# STM32L162ZDT6 register map
File version: 1.0
Registers are 32-bit, access not given, reset 0x0 unless marked. A register's access mark holds for its fields unless they carry their own. Offsets are from the block's base; [hi:lo] are bit positions; {n}, {i} and the like mark numbered series; 'fields as' and 'values as' point back to an identical list.

## GPIOA
Base 0x40020000
Same registers: GPIOB 0x40020400, GPIOC 0x40020800, GPIOD 0x40020C00, GPIOE 0x40021000, GPIOH 0x40021400, GPIOF 0x40021800, GPIOG 0x40021C00
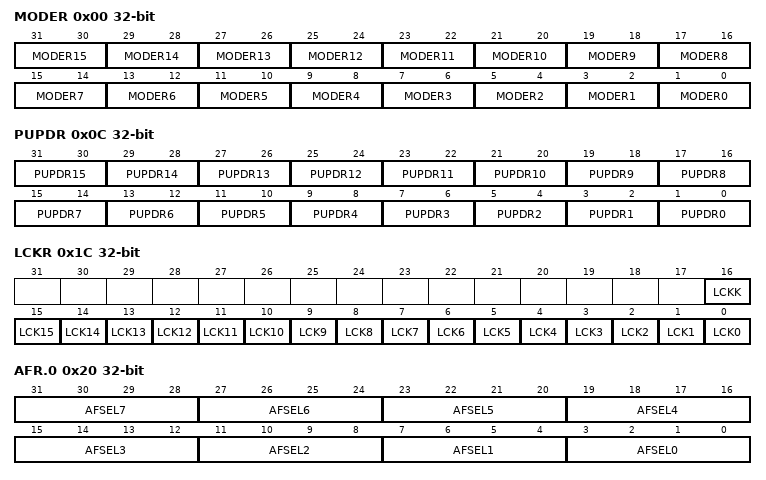
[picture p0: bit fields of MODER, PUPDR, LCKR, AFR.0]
0x00 MODER
  [2n+1:2n] MODER{n} (n=0..15)
0x04 OTYPER
0x08 OSPEEDR
0x0C PUPDR
  [2n+1:2n] PUPDR{n} (n=0..15)
0x10 IDR
0x14 ODR
0x18 BSRR
0x1C LCKR
  [16] LCKK, [n] LCK{n} (n=0..15)
0x20 AFR.0
  [4n+3:4n] AFSEL{n} (n=0..7)
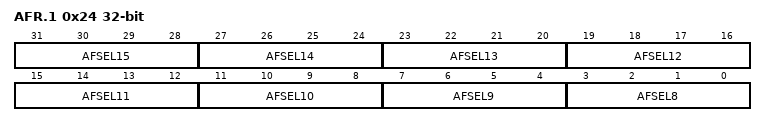
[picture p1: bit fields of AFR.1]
0x24 AFR.1
  [4n-29:4n-32] AFSEL{n} (n=8..15)
0x28 BRR

## CRC
Base 0x40023000
0x00 DR
0x04 IDR 8-bit
0x08 CR
  [0] RESET

## RCC
Base 0x40023800
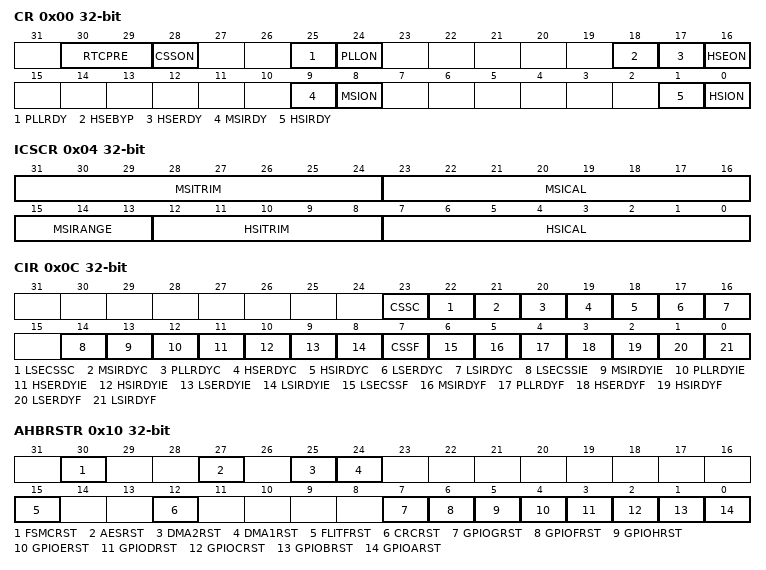
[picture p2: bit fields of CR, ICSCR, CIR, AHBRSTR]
0x00 CR
  [30:29] RTCPRE, [28] CSSON, [25] PLLRDY, [24] PLLON, [18] HSEBYP, [17] HSERDY, [16] HSEON, [9] MSIRDY, [8] MSION, [1] HSIRDY, [0] HSION
0x04 ICSCR
  [31:24] MSITRIM, [23:16] MSICAL, [15:13] MSIRANGE, [12:8] HSITRIM, [7:0] HSICAL
0x08 CFGR
  [30:28] MCOPRE, [26] MCOSEL_HSE, [26:25] MCOSEL_LSI, [24] MCOSEL_SYSCLK, [23] PLLDIV3, [23:22] PLLDIV4, [21:18] PLLMUL, [16] PLLSRC, [13:11] PPRE2, [10:8] PPRE1, [7:4] HPRE, [3:2] SWS, [1:0] SW
0x0C CIR
  [23] CSSC, [22] LSECSSC, [21] MSIRDYC, [20] PLLRDYC, [19] HSERDYC, [18] HSIRDYC, [17] LSERDYC, [16] LSIRDYC, [14] LSECSSIE, [13] MSIRDYIE, [12] PLLRDYIE, [11] HSERDYIE, [10] HSIRDYIE, [9] LSERDYIE, [8] LSIRDYIE, [7] CSSF, [6] LSECSSF, [5] MSIRDYF, [4] PLLRDYF, [3] HSERDYF, [2] HSIRDYF, [1] LSERDYF, [0] LSIRDYF
0x10 AHBRSTR
  [30] FSMCRST, [27] AESRST, [25] DMA2RST, [24] DMA1RST, [15] FLITFRST, [12] CRCRST, [7] GPIOGRST, [6] GPIOFRST, [5] GPIOHRST, [4] GPIOERST, [3] GPIODRST, [2] GPIOCRST, [1] GPIOBRST, [0] GPIOARST
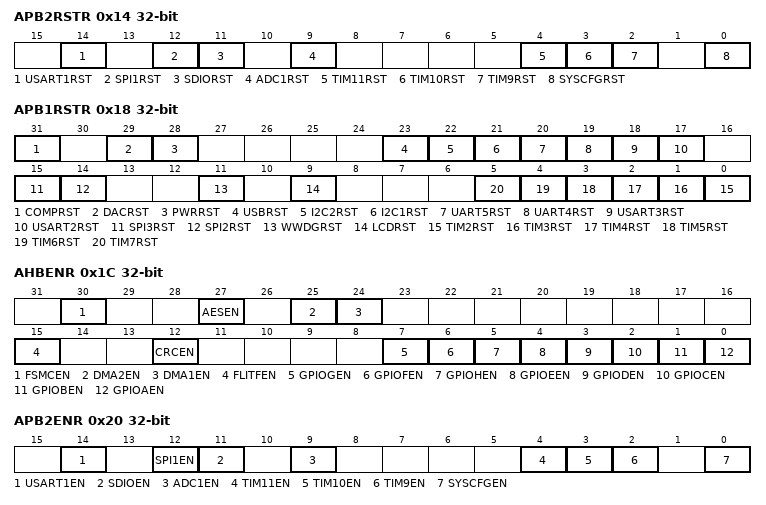
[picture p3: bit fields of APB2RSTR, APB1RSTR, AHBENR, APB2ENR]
0x14 APB2RSTR
  [14] USART1RST, [12] SPI1RST, [11] SDIORST, [9] ADC1RST, [4] TIM11RST, [3] TIM10RST, [2] TIM9RST, [0] SYSCFGRST
0x18 APB1RSTR
  [31] COMPRST, [29] DACRST, [28] PWRRST, [23] USBRST, [22] I2C2RST, [21] I2C1RST, [20] UART5RST, [19] UART4RST, [18] USART3RST, [17] USART2RST, [15] SPI3RST, [14] SPI2RST, [11] WWDGRST, [9] LCDRST, [n-2] TIM{n}RST (n=2..7)
0x1C AHBENR
  [30] FSMCEN, [27] AESEN, [25] DMA2EN, [24] DMA1EN, [15] FLITFEN, [12] CRCEN, [7] GPIOGEN, [6] GPIOFEN, [5] GPIOHEN, [4] GPIOEEN, [3] GPIODEN, [2] GPIOCEN, [1] GPIOBEN, [0] GPIOAEN
0x20 APB2ENR
  [14] USART1EN, [12] SPI1EN, [11] SDIOEN, [9] ADC1EN, [4] TIM11EN, [3] TIM10EN, [2] TIM9EN, [0] SYSCFGEN
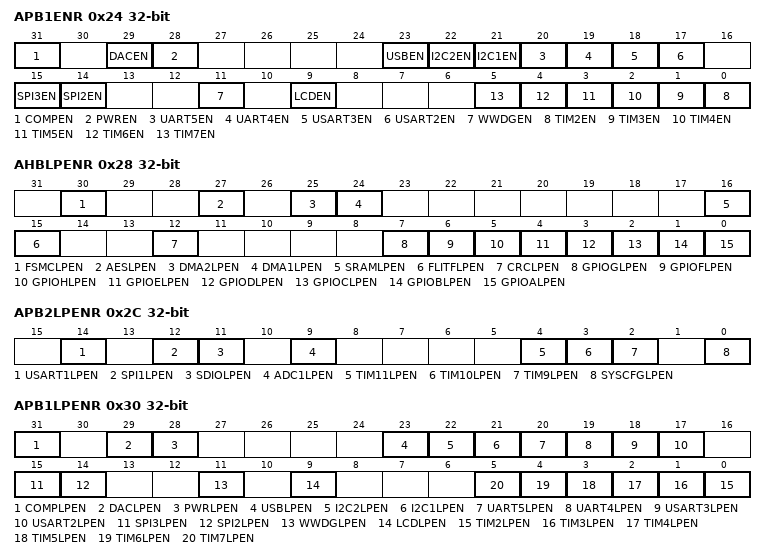
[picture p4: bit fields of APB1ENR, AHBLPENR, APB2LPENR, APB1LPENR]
0x24 APB1ENR
  [31] COMPEN, [29] DACEN, [28] PWREN, [23] USBEN, [22] I2C2EN, [21] I2C1EN, [20] UART5EN, [19] UART4EN, [18] USART3EN, [17] USART2EN, [15] SPI3EN, [14] SPI2EN, [11] WWDGEN, [9] LCDEN, [n-2] TIM{n}EN (n=2..7)
0x28 AHBLPENR
  [30] FSMCLPEN, [27] AESLPEN, [25] DMA2LPEN, [24] DMA1LPEN, [16] SRAMLPEN, [15] FLITFLPEN, [12] CRCLPEN, [7] GPIOGLPEN, [6] GPIOFLPEN, [5] GPIOHLPEN, [4] GPIOELPEN, [3] GPIODLPEN, [2] GPIOCLPEN, [1] GPIOBLPEN, [0] GPIOALPEN
0x2C APB2LPENR
  [14] USART1LPEN, [12] SPI1LPEN, [11] SDIOLPEN, [9] ADC1LPEN, [4] TIM11LPEN, [3] TIM10LPEN, [2] TIM9LPEN, [0] SYSCFGLPEN
0x30 APB1LPENR
  [31] COMPLPEN, [29] DACLPEN, [28] PWRLPEN, [23] USBLPEN, [22] I2C2LPEN, [21] I2C1LPEN, [20] UART5LPEN, [19] UART4LPEN, [18] USART3LPEN, [17] USART2LPEN, [15] SPI3LPEN, [14] SPI2LPEN, [11] WWDGLPEN, [9] LCDLPEN, [n-2] TIM{n}LPEN (n=2..7)
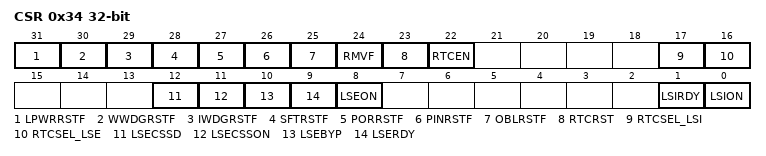
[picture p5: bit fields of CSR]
0x34 CSR
  [31] LPWRRSTF, [30] WWDGRSTF, [29] IWDGRSTF, [28] SFTRSTF, [27] PORRSTF, [26] PINRSTF, [25] OBLRSTF, [24] RMVF, [23] RTCRST, [22] RTCEN, [17] RTCSEL_LSI, [16] RTCSEL_LSE, [12] LSECSSD, [11] LSECSSON, [10] LSEBYP, [9] LSERDY, [8] LSEON, [1] LSIRDY, [0] LSION

## FLASH
Base 0x40023C00
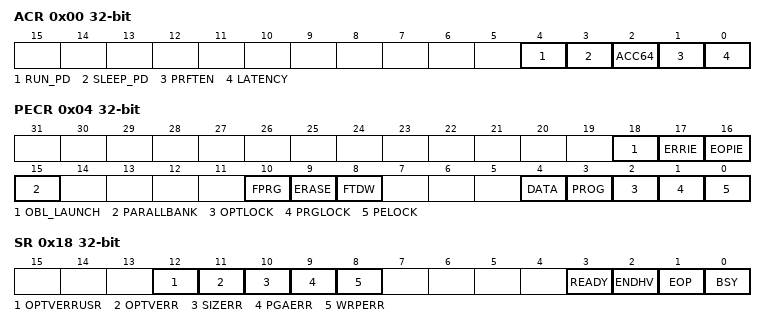
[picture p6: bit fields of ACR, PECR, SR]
0x00 ACR
  [4] RUN_PD, [3] SLEEP_PD, [2] ACC64, [1] PRFTEN, [0] LATENCY
0x04 PECR
  [18] OBL_LAUNCH, [17] ERRIE, [16] EOPIE, [15] PARALLBANK, [10] FPRG, [9] ERASE, [8] FTDW, [4] DATA, [3] PROG, [2] OPTLOCK, [1] PRGLOCK, [0] PELOCK
0x08 PDKEYR
0x0C PEKEYR
0x10 PRGKEYR
0x14 OPTKEYR
0x18 SR
  [12] OPTVERRUSR, [11] OPTVERR, [10] SIZERR, [9] PGAERR, [8] WRPERR, [3] READY, [2] ENDHV, [1] EOP, [0] BSY
0x1C OBR
  [23] nRST_BFB2, [22] nRST_STDBY, [21] nRST_STOP, [23:20] USER, [19:16] BOR_LEV, [7:0] RDPRT
0x20 WRPR1
  [31:0] WRP
0x80 WRPR2
  [31:0] WRP
0x84 WRPR3
  [31:0] WRP

## DMA1
Base 0x40026000
Same registers: DMA2 0x40026400
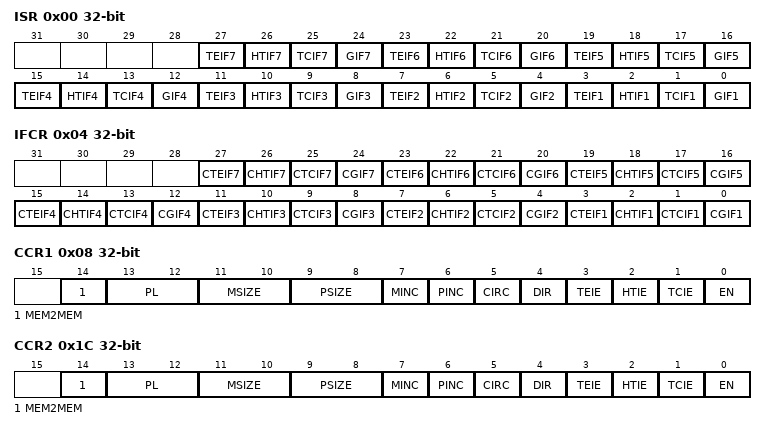
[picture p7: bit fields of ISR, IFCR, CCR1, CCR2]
0x00 ISR
  [4n-1] TEIF{n} (n=1..7), [4n-2] HTIF{n} (n=1..7), [4n-3] TCIF{n} (n=1..7), [4n-4] GIF{n} (n=1..7)
0x04 IFCR
  [4n-1] CTEIF{n} (n=1..7), [4n-2] CHTIF{n} (n=1..7), [4n-3] CTCIF{n} (n=1..7), [4n-4] CGIF{n} (n=1..7)
0x08 CCR1
  [14] MEM2MEM, [13:12] PL, [11:10] MSIZE, [9:8] PSIZE, [7] MINC, [6] PINC, [5] CIRC, [4] DIR, [3] TEIE, [2] HTIE, [1] TCIE, [0] EN
0x0C CNDTR1
  [15:0] NDT
0x10 CPAR1
  [31:0] PA
{0x0+0x14*i} CMAR{i} (i=1..7)
  [31:0] MA
0x1C CCR2
  fields as CCR1
0x20 CNDTR2
  [15:0] NDT
0x24 CPAR2
  [31:0] PA
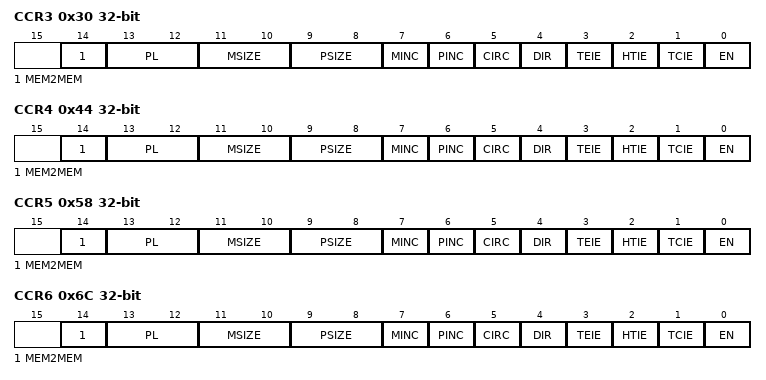
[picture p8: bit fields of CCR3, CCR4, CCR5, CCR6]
0x30 CCR3
  fields as CCR1
0x34 CNDTR3
  [15:0] NDT
0x38 CPAR3
  [31:0] PA
0x44 CCR4
  fields as CCR1
0x48 CNDTR4
  [15:0] NDT
0x4C CPAR4
  [31:0] PA
0x58 CCR5
  fields as CCR1
0x5C CNDTR5
  [15:0] NDT
0x60 CPAR5
  [31:0] PA
0x6C CCR6
  fields as CCR1
0x70 CNDTR6
  [15:0] NDT
0x74 CPAR6
  [31:0] PA
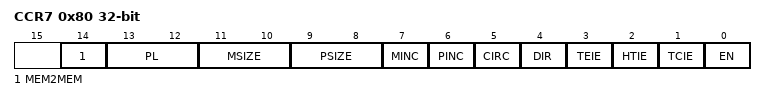
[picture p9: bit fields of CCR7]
0x80 CCR7
  fields as CCR1
0x84 CNDTR7
  [15:0] NDT
0x88 CPAR7
  [31:0] PA

## AES
Base 0x50060000
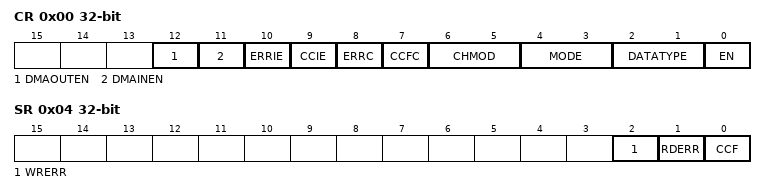
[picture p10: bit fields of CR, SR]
0x00 CR
  [12] DMAOUTEN, [11] DMAINEN, [10] ERRIE, [9] CCIE, [8] ERRC, [7] CCFC, [6:5] CHMOD, [4:3] MODE, [2:1] DATATYPE, [0] EN
0x04 SR
  [2] WRERR, [1] RDERR, [0] CCF
0x08 DINR
0x0C DOUTR
{0x10+4i} KEYR{i} (i=0..3)
{0x20+4i} IVR{i} (i=0..3)

## FSMC_Bank1
Base 0xA0000000
0x00 BTCR.0
  [29:28] ACCMOD, [27:24] DATLAT, [23:20] CLKDIV, [19] CBURSTRW, [18:16] CPSIZE, [15] ASYNCWAIT, [14] EXTMOD, [13] WAITEN, [12] WREN, [11] WAITCFG, [10] WRAPMOD, [9] WAITPOL, [15:8] DATAST, [6] FACCEN, [5:4] MWID, [3:2] MTYP, [1] MUXEN, [0] MBKEN
0x04 BTCR.1
  fields as BTCR.0
0x08 BTCR.2
  fields as BTCR.0
0x0C BTCR.3
  fields as BTCR.0
0x10 BTCR.4
  fields as BTCR.0
0x14 BTCR.5
  fields as BTCR.0
0x18 BTCR.6
  fields as BTCR.0
0x1C BTCR.7
  fields as BTCR.0

## FSMC_Bank1E
Base 0xA0000104
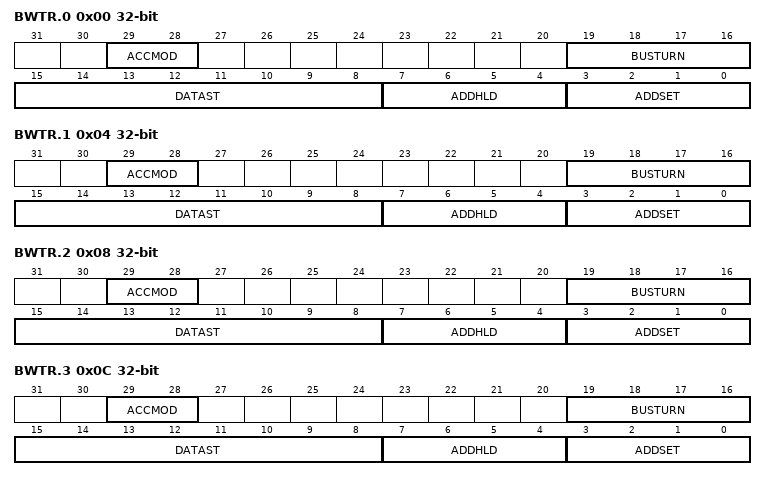
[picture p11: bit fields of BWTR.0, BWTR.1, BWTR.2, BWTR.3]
0x00 BWTR.0
  [29:28] ACCMOD, [19:16] BUSTURN, [15:8] DATAST, [7:4] ADDHLD, [3:0] ADDSET
0x04 BWTR.1
  fields as BWTR.0
0x08 BWTR.2
  fields as BWTR.0
0x0C BWTR.3
  fields as BWTR.0
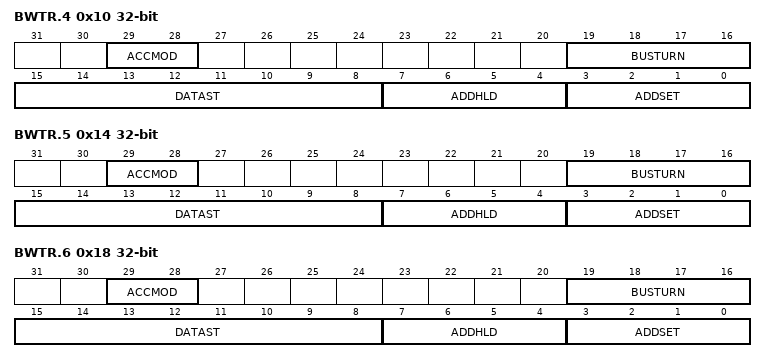
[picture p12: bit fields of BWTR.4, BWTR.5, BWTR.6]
0x10 BWTR.4
  fields as BWTR.0
0x14 BWTR.5
  fields as BWTR.0
0x18 BWTR.6
  fields as BWTR.0

## DBGMCU
Base 0xE0042000
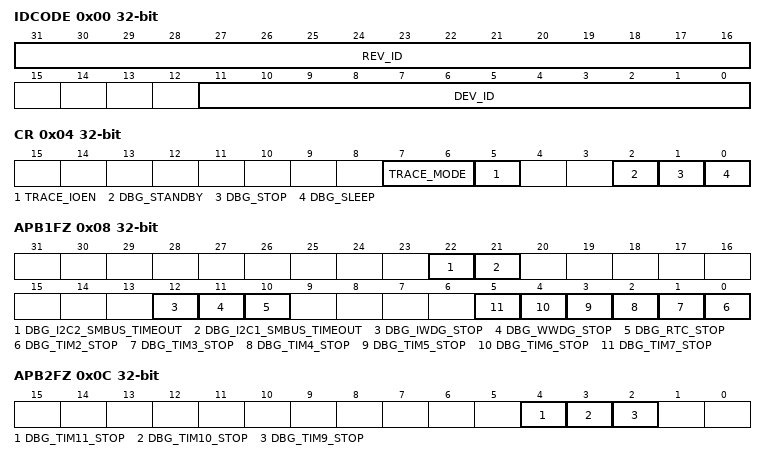
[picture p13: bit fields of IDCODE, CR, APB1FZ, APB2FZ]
0x00 IDCODE
  [31:16] REV_ID, [11:0] DEV_ID
0x04 CR
  [7:6] TRACE_MODE, [5] TRACE_IOEN, [2] DBG_STANDBY, [1] DBG_STOP, [0] DBG_SLEEP
0x08 APB1FZ
  [22] DBG_I2C2_SMBUS_TIMEOUT, [21] DBG_I2C1_SMBUS_TIMEOUT, [12] DBG_IWDG_STOP, [11] DBG_WWDG_STOP, [10] DBG_RTC_STOP, [n-2] DBG_TIM{n}_STOP (n=2..7)
0x0C APB2FZ
  [4] DBG_TIM11_STOP, [3] DBG_TIM10_STOP, [2] DBG_TIM9_STOP
